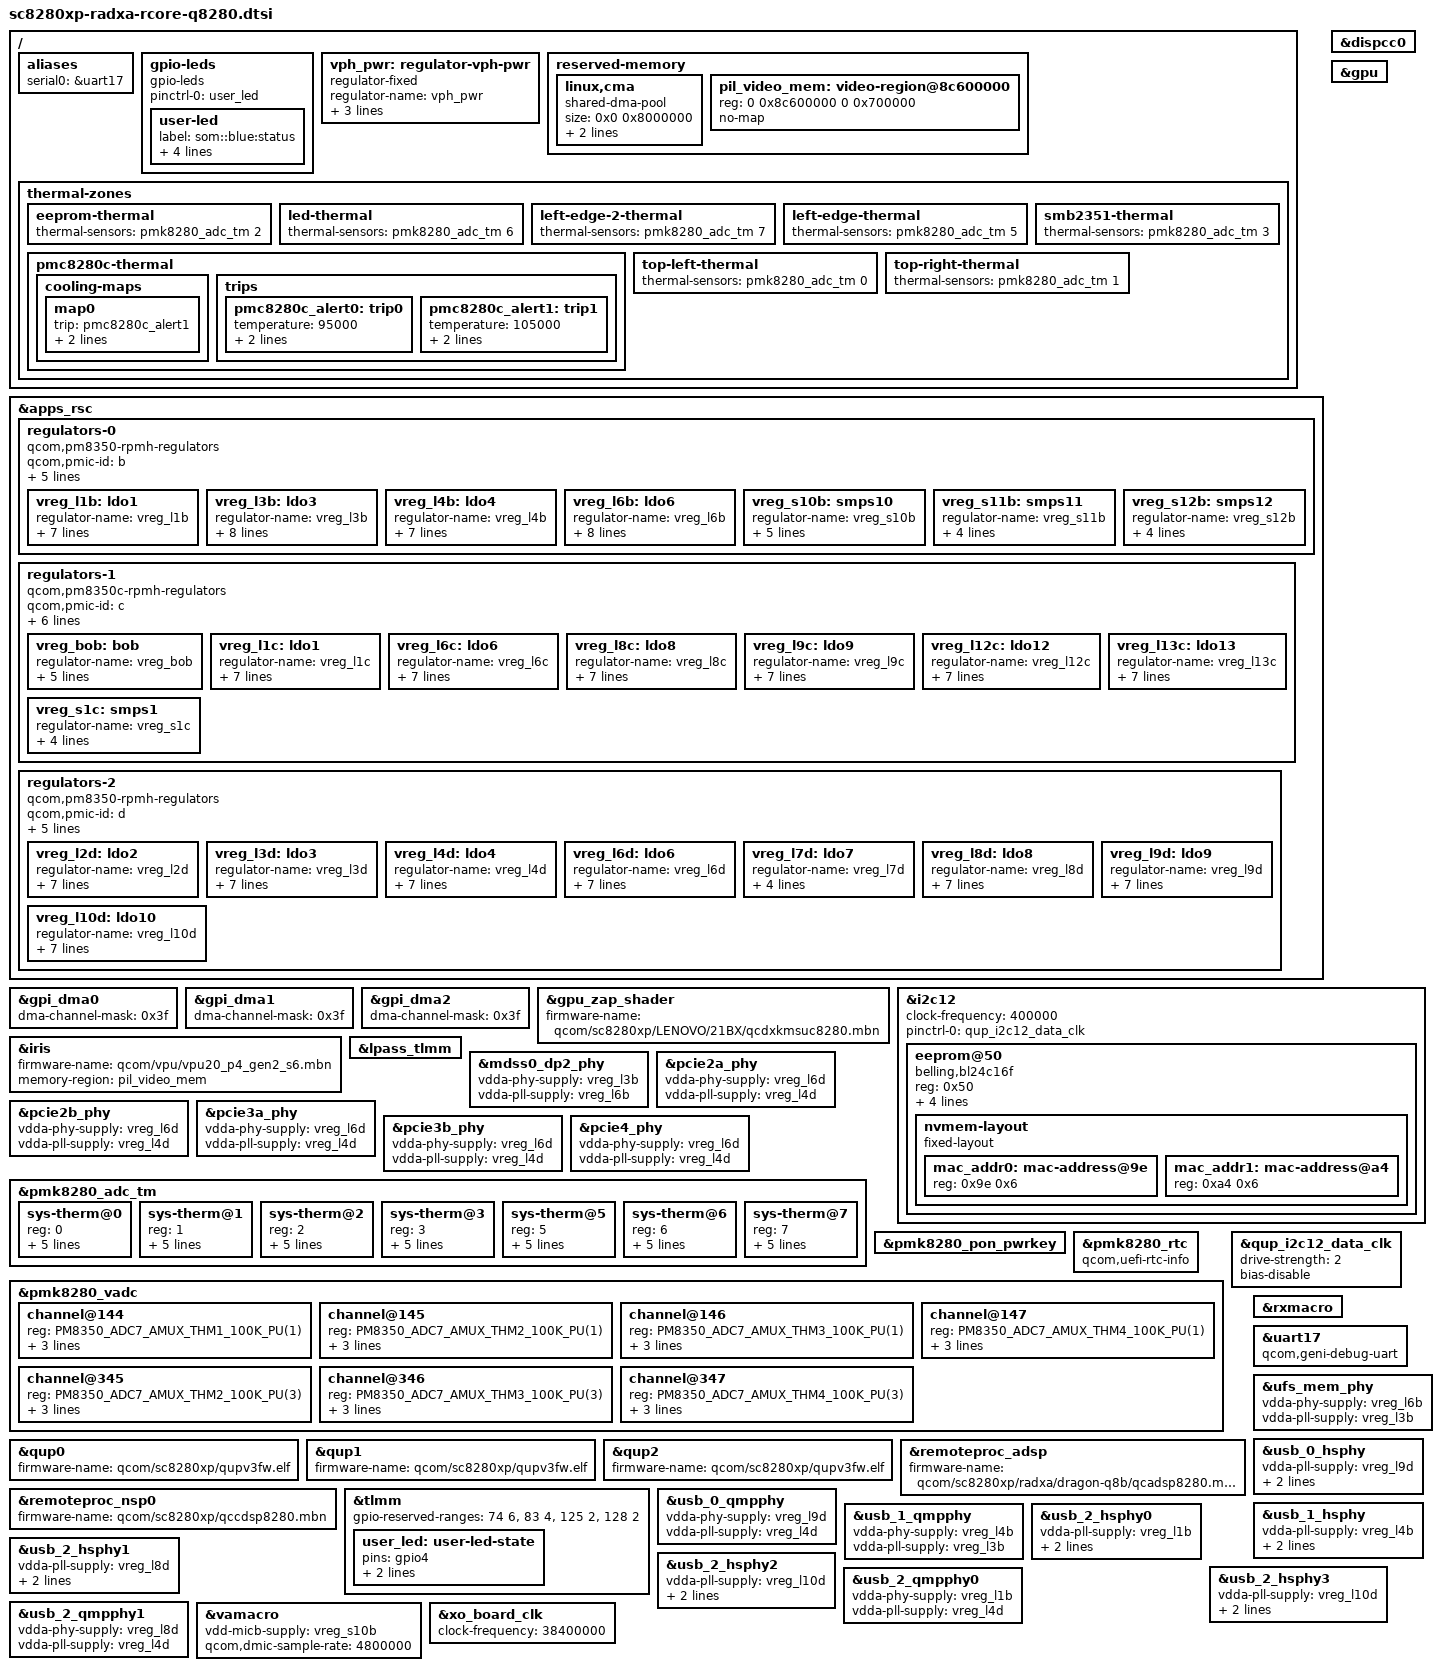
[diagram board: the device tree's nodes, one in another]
// SPDX-License-Identifier: BSD-3-Clause
/*
 * Copyright (c) 2026 Radxa Computer (Shenzhen) Co., Ltd.
 */

#include <dt-bindings/gpio/gpio.h>
#include <dt-bindings/leds/common.h>
#include <dt-bindings/regulator/qcom,rpmh-regulator.h>

#include "sc8280xp.dtsi"
#include "sc8280xp-pmics.dtsi"

/delete-node/ &pil_video_mem;
/delete-node/ &pil_nsp1_mem;
/delete-node/ &remoteproc_nsp1;

/ {
	aliases {
		serial0 = &uart17;
	};

	gpio-leds {
		compatible = "gpio-leds";
		pinctrl-0 = <&user_led>;
		pinctrl-names = "default";

		user-led {
			label = "som::blue:status";
			color = <LED_COLOR_ID_BLUE>;
			function = LED_FUNCTION_STATUS;
			gpios = <&tlmm 4 GPIO_ACTIVE_HIGH>;
			linux,default-trigger = "heartbeat";
		};
	};

	vph_pwr: regulator-vph-pwr {
		compatible = "regulator-fixed";
		regulator-name = "vph_pwr";
		regulator-min-microvolt = <4200000>;
		regulator-max-microvolt = <4200000>;
		regulator-always-on;
	};

	reserved-memory {
		linux,cma {
			compatible = "shared-dma-pool";
			size = <0x0 0x8000000>;
			reusable;
			linux,cma-default;
		};

		pil_video_mem: video-region@8c600000 {
			reg = <0 0x8c600000 0 0x700000>;
			no-map;
		};
	};

	thermal-zones {
		eeprom-thermal {
			thermal-sensors = <&pmk8280_adc_tm 2>;
		};

		led-thermal {
			thermal-sensors = <&pmk8280_adc_tm 6>;
		};

		left-edge-2-thermal {
			thermal-sensors = <&pmk8280_adc_tm 7>;
		};

		left-edge-thermal {
			thermal-sensors = <&pmk8280_adc_tm 5>;
		};

		pmc8280c-thermal {
			cooling-maps {
				map0 {
					trip = <&pmc8280c_alert1>;
					/* Throttle X1C cores to 2496MHz at 105C */
					cooling-device = <&cpu4 5 5>,
							 <&cpu5 5 5>,
							 <&cpu6 5 5>,
							 <&cpu7 5 5>;
				};
			};

			trips {
				pmc8280c_alert0: trip0 {
					temperature = <95000>;
					hysteresis = <0>;
					type = "passive";
				};

				pmc8280c_alert1: trip1 {
					temperature = <105000>;
					hysteresis = <0>;
					type = "passive";
				};
			};
		};

		smb2351-thermal {
			thermal-sensors = <&pmk8280_adc_tm 3>;
		};

		top-left-thermal {
			thermal-sensors = <&pmk8280_adc_tm 0>;
		};

		top-right-thermal {
			thermal-sensors = <&pmk8280_adc_tm 1>;
		};
	};
};

&apps_rsc {
	regulators-0 {
		compatible = "qcom,pm8350-rpmh-regulators";
		qcom,pmic-id = "b";
		vdd-l1-l4-supply = <&vreg_s12b>;
		vdd-l2-l7-supply = <&vreg_bob>;
		vdd-l3-l5-supply = <&vreg_s11b>;
		vdd-l6-l9-l10-supply = <&vreg_s12b>;
		vdd-l8-supply = <&vreg_s12b>;

		vreg_l1b: ldo1 {
			regulator-name = "vreg_l1b";
			regulator-min-microvolt = <912000>;
			regulator-max-microvolt = <912000>;
			regulator-initial-mode = <RPMH_REGULATOR_MODE_HPM>;
			regulator-allow-set-load;
			regulator-allowed-modes = <RPMH_REGULATOR_MODE_LPM
						   RPMH_REGULATOR_MODE_HPM>;
		};

		vreg_l3b: ldo3 {
			regulator-name = "vreg_l3b";
			regulator-min-microvolt = <1200000>;
			regulator-max-microvolt = <1200000>;
			regulator-initial-mode = <RPMH_REGULATOR_MODE_HPM>;
			regulator-boot-on;
			regulator-allow-set-load;
			regulator-allowed-modes = <RPMH_REGULATOR_MODE_LPM
						   RPMH_REGULATOR_MODE_HPM>;
		};

		vreg_l4b: ldo4 {
			regulator-name = "vreg_l4b";
			regulator-min-microvolt = <912000>;
			regulator-max-microvolt = <912000>;
			regulator-initial-mode = <RPMH_REGULATOR_MODE_HPM>;
			regulator-allow-set-load;
			regulator-allowed-modes = <RPMH_REGULATOR_MODE_LPM
						   RPMH_REGULATOR_MODE_HPM>;
		};

		vreg_l6b: ldo6 {
			regulator-name = "vreg_l6b";
			regulator-min-microvolt = <880000>;
			regulator-max-microvolt = <880000>;
			regulator-initial-mode = <RPMH_REGULATOR_MODE_HPM>;
			regulator-boot-on;
			regulator-allow-set-load;
			regulator-allowed-modes = <RPMH_REGULATOR_MODE_LPM
						   RPMH_REGULATOR_MODE_HPM>;
		};

		vreg_s10b: smps10 {
			regulator-name = "vreg_s10b";
			regulator-min-microvolt = <1800000>;
			regulator-max-microvolt = <1800000>;
			regulator-initial-mode = <RPMH_REGULATOR_MODE_HPM>;
			regulator-always-on;
		};

		vreg_s11b: smps11 {
			regulator-name = "vreg_s11b";
			regulator-min-microvolt = <1272000>;
			regulator-max-microvolt = <1272000>;
			regulator-initial-mode = <RPMH_REGULATOR_MODE_HPM>;
		};

		vreg_s12b: smps12 {
			regulator-name = "vreg_s12b";
			regulator-min-microvolt = <984000>;
			regulator-max-microvolt = <984000>;
			regulator-initial-mode = <RPMH_REGULATOR_MODE_HPM>;
		};
	};

	regulators-1 {
		compatible = "qcom,pm8350c-rpmh-regulators";
		qcom,pmic-id = "c";
		vdd-bob-supply = <&vph_pwr>;
		vdd-l1-l12-supply = <&vreg_s1c>;
		vdd-l2-l8-supply = <&vreg_s1c>;
		vdd-l3-l4-l5-l7-l13-supply = <&vreg_bob>;
		vdd-l6-l9-l11-supply = <&vreg_bob>;
		vdd-l10-supply = <&vreg_s11b>;

		vreg_bob: bob {
			regulator-name = "vreg_bob";
			regulator-min-microvolt = <3008000>;
			regulator-max-microvolt = <3960000>;
			regulator-initial-mode = <RPMH_REGULATOR_MODE_AUTO>;
			regulator-always-on;
		};

		vreg_l1c: ldo1 {
			regulator-name = "vreg_l1c";
			regulator-min-microvolt = <1800000>;
			regulator-max-microvolt = <1800000>;
			regulator-initial-mode = <RPMH_REGULATOR_MODE_HPM>;
			regulator-allow-set-load;
			regulator-allowed-modes = <RPMH_REGULATOR_MODE_LPM
						   RPMH_REGULATOR_MODE_HPM>;
		};

		vreg_l6c: ldo6 {
			regulator-name = "vreg_l6c";
			regulator-min-microvolt = <1800000>;
			regulator-max-microvolt = <2960000>;
			regulator-initial-mode = <RPMH_REGULATOR_MODE_HPM>;
			regulator-allow-set-load;
			regulator-allowed-modes = <RPMH_REGULATOR_MODE_LPM
						   RPMH_REGULATOR_MODE_HPM>;
		};

		vreg_l8c: ldo8 {
			regulator-name = "vreg_l8c";
			regulator-min-microvolt = <1800000>;
			regulator-max-microvolt = <1800000>;
			regulator-initial-mode = <RPMH_REGULATOR_MODE_HPM>;
			regulator-allow-set-load;
			regulator-allowed-modes = <RPMH_REGULATOR_MODE_LPM
						   RPMH_REGULATOR_MODE_HPM>;
		};

		vreg_l9c: ldo9 {
			regulator-name = "vreg_l9c";
			regulator-min-microvolt = <2960000>;
			regulator-max-microvolt = <2960000>;
			regulator-initial-mode = <RPMH_REGULATOR_MODE_HPM>;
			regulator-allow-set-load;
			regulator-allowed-modes = <RPMH_REGULATOR_MODE_LPM
						   RPMH_REGULATOR_MODE_HPM>;
		};

		vreg_l12c: ldo12 {
			regulator-name = "vreg_l12c";
			regulator-min-microvolt = <1800000>;
			regulator-max-microvolt = <1800000>;
			regulator-initial-mode = <RPMH_REGULATOR_MODE_HPM>;
			regulator-allow-set-load;
			regulator-allowed-modes = <RPMH_REGULATOR_MODE_LPM
						   RPMH_REGULATOR_MODE_HPM>;
		};

		vreg_l13c: ldo13 {
			regulator-name = "vreg_l13c";
			regulator-min-microvolt = <3072000>;
			regulator-max-microvolt = <3072000>;
			regulator-initial-mode = <RPMH_REGULATOR_MODE_HPM>;
			regulator-allow-set-load;
			regulator-allowed-modes = <RPMH_REGULATOR_MODE_LPM
						   RPMH_REGULATOR_MODE_HPM>;
		};

		vreg_s1c: smps1 {
			regulator-name = "vreg_s1c";
			regulator-min-microvolt = <1888000>;
			regulator-max-microvolt = <1888000>;
			regulator-initial-mode = <RPMH_REGULATOR_MODE_HPM>;
		};
	};

	regulators-2 {
		compatible = "qcom,pm8350-rpmh-regulators";
		qcom,pmic-id = "d";
		vdd-l1-l4-supply = <&vreg_s11b>;
		vdd-l2-l7-supply = <&vreg_bob>;
		vdd-l3-l5-supply = <&vreg_s11b>;
		vdd-l6-l9-l10-supply = <&vreg_s12b>;
		vdd-l8-supply = <&vreg_s12b>;

		vreg_l2d: ldo2 {
			regulator-name = "vreg_l2d";
			regulator-min-microvolt = <3072000>;
			regulator-max-microvolt = <3072000>;
			regulator-initial-mode = <RPMH_REGULATOR_MODE_HPM>;
			regulator-allow-set-load;
			regulator-allowed-modes = <RPMH_REGULATOR_MODE_LPM
						   RPMH_REGULATOR_MODE_HPM>;
		};

		vreg_l3d: ldo3 {
			regulator-name = "vreg_l3d";
			regulator-min-microvolt = <1200000>;
			regulator-max-microvolt = <1200000>;
			regulator-initial-mode = <RPMH_REGULATOR_MODE_HPM>;
			regulator-allow-set-load;
			regulator-allowed-modes = <RPMH_REGULATOR_MODE_LPM
						   RPMH_REGULATOR_MODE_HPM>;
		};

		vreg_l4d: ldo4 {
			regulator-name = "vreg_l4d";
			regulator-min-microvolt = <1200000>;
			regulator-max-microvolt = <1200000>;
			regulator-initial-mode = <RPMH_REGULATOR_MODE_HPM>;
			regulator-allow-set-load;
			regulator-allowed-modes = <RPMH_REGULATOR_MODE_LPM
						   RPMH_REGULATOR_MODE_HPM>;
		};

		vreg_l6d: ldo6 {
			regulator-name = "vreg_l6d";
			regulator-min-microvolt = <880000>;
			regulator-max-microvolt = <880000>;
			regulator-initial-mode = <RPMH_REGULATOR_MODE_HPM>;
			regulator-allow-set-load;
			regulator-allowed-modes = <RPMH_REGULATOR_MODE_LPM
						   RPMH_REGULATOR_MODE_HPM>;
		};

		vreg_l7d: ldo7 {
			regulator-name = "vreg_l7d";
			regulator-min-microvolt = <3072000>;
			regulator-max-microvolt = <3072000>;
			regulator-initial-mode = <RPMH_REGULATOR_MODE_HPM>;
		};

		vreg_l8d: ldo8 {
			regulator-name = "vreg_l8d";
			regulator-min-microvolt = <912000>;
			regulator-max-microvolt = <912000>;
			regulator-initial-mode = <RPMH_REGULATOR_MODE_HPM>;
			regulator-allow-set-load;
			regulator-allowed-modes = <RPMH_REGULATOR_MODE_LPM
						   RPMH_REGULATOR_MODE_HPM>;
		};

		vreg_l9d: ldo9 {
			regulator-name = "vreg_l9d";
			regulator-min-microvolt = <912000>;
			regulator-max-microvolt = <912000>;
			regulator-initial-mode = <RPMH_REGULATOR_MODE_HPM>;
			regulator-allow-set-load;
			regulator-allowed-modes = <RPMH_REGULATOR_MODE_LPM
						   RPMH_REGULATOR_MODE_HPM>;
		};

		vreg_l10d: ldo10 {
			regulator-name = "vreg_l10d";
			regulator-min-microvolt = <912000>;
			regulator-max-microvolt = <912000>;
			regulator-initial-mode = <RPMH_REGULATOR_MODE_HPM>;
			regulator-allow-set-load;
			regulator-allowed-modes = <RPMH_REGULATOR_MODE_LPM
						   RPMH_REGULATOR_MODE_HPM>;
		};
	};
};

&dispcc0 {
	status = "okay";
};

&gpi_dma0 {
	dma-channel-mask = <0x3f>;
	status = "okay";
};

&gpi_dma1 {
	dma-channel-mask = <0x3f>;
	status = "okay";
};

&gpi_dma2 {
	dma-channel-mask = <0x3f>;
	status = "okay";
};

&gpu {
	status = "okay";
};

&gpu_zap_shader {
	/* Reuse firmware from x13s as the SoC is unfused */
	firmware-name = "qcom/sc8280xp/LENOVO/21BX/qcdxkmsuc8280.mbn";
};

&i2c12 {
	clock-frequency = <400000>;
	pinctrl-0 = <&qup_i2c12_data_clk>;
	pinctrl-names = "default";
	status = "okay";

	eeprom@50 {
		compatible = "belling,bl24c16f", "atmel,24c16";
		reg = <0x50>;
		pagesize = <16>;
		vcc-supply = <&vreg_s10b>;
		wp-gpios = <&tlmm 3 GPIO_ACTIVE_LOW>;
		read-only;

		nvmem-layout {
			compatible = "fixed-layout";
			#address-cells = <1>;
			#size-cells = <1>;

			mac_addr0: mac-address@9e {
				reg = <0x9e 0x6>;
			};

			mac_addr1: mac-address@a4 {
				reg = <0xa4 0x6>;
			};
		};
	};
};

&iris {
	firmware-name = "qcom/vpu/vpu20_p4_gen2_s6.mbn";
	memory-region = <&pil_video_mem>;
	status = "okay";
};

&lpass_tlmm {
	status = "okay";
};

&mdss0_dp2_phy {
	vdda-phy-supply = <&vreg_l3b>;
	vdda-pll-supply = <&vreg_l6b>;
};

&pcie2a_phy {
	vdda-phy-supply = <&vreg_l6d>;
	vdda-pll-supply = <&vreg_l4d>;
};

&pcie2b_phy {
	vdda-phy-supply = <&vreg_l6d>;
	vdda-pll-supply = <&vreg_l4d>;
};

&pcie3a_phy {
	vdda-phy-supply = <&vreg_l6d>;
	vdda-pll-supply = <&vreg_l4d>;
};

&pcie3b_phy {
	vdda-phy-supply = <&vreg_l6d>;
	vdda-pll-supply = <&vreg_l4d>;
};

&pcie4_phy {
	vdda-phy-supply = <&vreg_l6d>;
	vdda-pll-supply = <&vreg_l4d>;
};

&pmk8280_adc_tm {
	status = "okay";

	sys-therm@0 {
		reg = <0>;
		io-channels = <&pmk8280_vadc PM8350_ADC7_AMUX_THM1_100K_PU(1)>;
		qcom,hw-settle-time-us = <200>;
		qcom,avg-samples = <2>;
		qcom,ratiometric;
	};

	sys-therm@1 {
		reg = <1>;
		io-channels = <&pmk8280_vadc PM8350_ADC7_AMUX_THM2_100K_PU(1)>;
		qcom,hw-settle-time-us = <200>;
		qcom,avg-samples = <2>;
		qcom,ratiometric;
	};

	sys-therm@2 {
		reg = <2>;
		io-channels = <&pmk8280_vadc PM8350_ADC7_AMUX_THM3_100K_PU(1)>;
		qcom,hw-settle-time-us = <200>;
		qcom,avg-samples = <2>;
		qcom,ratiometric;
	};

	sys-therm@3 {
		reg = <3>;
		io-channels = <&pmk8280_vadc PM8350_ADC7_AMUX_THM4_100K_PU(1)>;
		qcom,hw-settle-time-us = <200>;
		qcom,avg-samples = <2>;
		qcom,ratiometric;
	};

	sys-therm@5 {
		reg = <5>;
		io-channels = <&pmk8280_vadc PM8350_ADC7_AMUX_THM2_100K_PU(3)>;
		qcom,hw-settle-time-us = <200>;
		qcom,avg-samples = <2>;
		qcom,ratiometric;
	};

	sys-therm@6 {
		reg = <6>;
		io-channels = <&pmk8280_vadc PM8350_ADC7_AMUX_THM3_100K_PU(3)>;
		qcom,hw-settle-time-us = <200>;
		qcom,avg-samples = <2>;
		qcom,ratiometric;
	};

	sys-therm@7 {
		reg = <7>;
		io-channels = <&pmk8280_vadc PM8350_ADC7_AMUX_THM4_100K_PU(3)>;
		qcom,hw-settle-time-us = <200>;
		qcom,avg-samples = <2>;
		qcom,ratiometric;
	};
};

&pmk8280_pon_pwrkey {
	status = "okay";
};

&pmk8280_rtc {
	qcom,uefi-rtc-info;
};

&pmk8280_vadc {
	channel@144 {
		reg = <PM8350_ADC7_AMUX_THM1_100K_PU(1)>;
		qcom,hw-settle-time = <200>;
		qcom,ratiometric;
		label = "sys_therm1";
	};

	channel@145 {
		reg = <PM8350_ADC7_AMUX_THM2_100K_PU(1)>;
		qcom,hw-settle-time = <200>;
		qcom,ratiometric;
		label = "sys_therm2";
	};

	channel@146 {
		reg = <PM8350_ADC7_AMUX_THM3_100K_PU(1)>;
		qcom,hw-settle-time = <200>;
		qcom,ratiometric;
		label = "sys_therm3";
	};

	channel@147 {
		reg = <PM8350_ADC7_AMUX_THM4_100K_PU(1)>;
		qcom,hw-settle-time = <200>;
		qcom,ratiometric;
		label = "sys_therm4";
	};

	channel@345 {
		reg = <PM8350_ADC7_AMUX_THM2_100K_PU(3)>;
		qcom,hw-settle-time = <200>;
		qcom,ratiometric;
		label = "sys_therm6";
	};

	channel@346 {
		reg = <PM8350_ADC7_AMUX_THM3_100K_PU(3)>;
		qcom,hw-settle-time = <200>;
		qcom,ratiometric;
		label = "sys_therm7";
	};

	channel@347 {
		reg = <PM8350_ADC7_AMUX_THM4_100K_PU(3)>;
		qcom,hw-settle-time = <200>;
		qcom,ratiometric;
		label = "sys_therm8";
	};
};

&qup0 {
	firmware-name = "qcom/sc8280xp/qupv3fw.elf";
	status = "okay";
};

&qup1 {
	firmware-name = "qcom/sc8280xp/qupv3fw.elf";
	status = "okay";
};

&qup2 {
	firmware-name = "qcom/sc8280xp/qupv3fw.elf";
	status = "okay";
};

&qup_i2c12_data_clk {
	drive-strength = <2>;
	bias-disable;
};

/* PINCTRL - additions to nodes defined in sc8280xp.dtsi */

&remoteproc_adsp {
	/* Radxa rCore-Q8280 currently reuses the validated Dragon Q8B ADSP firmware. */
	firmware-name = "qcom/sc8280xp/radxa/dragon-q8b/qcadsp8280.mbn";
	status = "okay";
};

&remoteproc_nsp0 {
	firmware-name = "qcom/sc8280xp/qccdsp8280.mbn";
	status = "okay";
};

&rxmacro {
	status = "okay";
};

&tlmm {
	gpio-reserved-ranges = <74 6>, <83 4>, <125 2>, <128 2>;

	user_led: user-led-state {
		pins = "gpio4";
		function = "gpio";
		bias-pull-up;
	};
};

&uart17 {
	compatible = "qcom,geni-debug-uart";
	status = "okay";
};

&ufs_mem_phy {
	vdda-phy-supply = <&vreg_l6b>;
	vdda-pll-supply = <&vreg_l3b>;
};

&usb_0_hsphy {
	vdda-pll-supply = <&vreg_l9d>;
	vdda18-supply = <&vreg_l1c>;
	vdda33-supply = <&vreg_l7d>;
};

&usb_0_qmpphy {
	vdda-phy-supply = <&vreg_l9d>;
	vdda-pll-supply = <&vreg_l4d>;
};

&usb_1_hsphy {
	vdda-pll-supply = <&vreg_l4b>;
	vdda18-supply = <&vreg_l1c>;
	vdda33-supply = <&vreg_l13c>;
};

&usb_1_qmpphy {
	vdda-phy-supply = <&vreg_l4b>;
	vdda-pll-supply = <&vreg_l3b>;
};

&usb_2_hsphy0 {
	vdda-pll-supply = <&vreg_l1b>;
	vdda18-supply = <&vreg_l1c>;
	vdda33-supply = <&vreg_l7d>;
};

&usb_2_hsphy1 {
	vdda-pll-supply = <&vreg_l8d>;
	vdda18-supply = <&vreg_l1c>;
	vdda33-supply = <&vreg_l7d>;
};

&usb_2_hsphy2 {
	vdda-pll-supply = <&vreg_l10d>;
	vdda18-supply = <&vreg_l8c>;
	vdda33-supply = <&vreg_l2d>;
};

&usb_2_hsphy3 {
	vdda-pll-supply = <&vreg_l10d>;
	vdda18-supply = <&vreg_l8c>;
	vdda33-supply = <&vreg_l2d>;
};

&usb_2_qmpphy0 {
	vdda-phy-supply = <&vreg_l1b>;
	vdda-pll-supply = <&vreg_l4d>;
};

&usb_2_qmpphy1 {
	vdda-phy-supply = <&vreg_l8d>;
	vdda-pll-supply = <&vreg_l4d>;
};

&vamacro {
	vdd-micb-supply = <&vreg_s10b>;
	qcom,dmic-sample-rate = <4800000>;
	status = "okay";
};

&xo_board_clk {
	clock-frequency = <38400000>;
};
